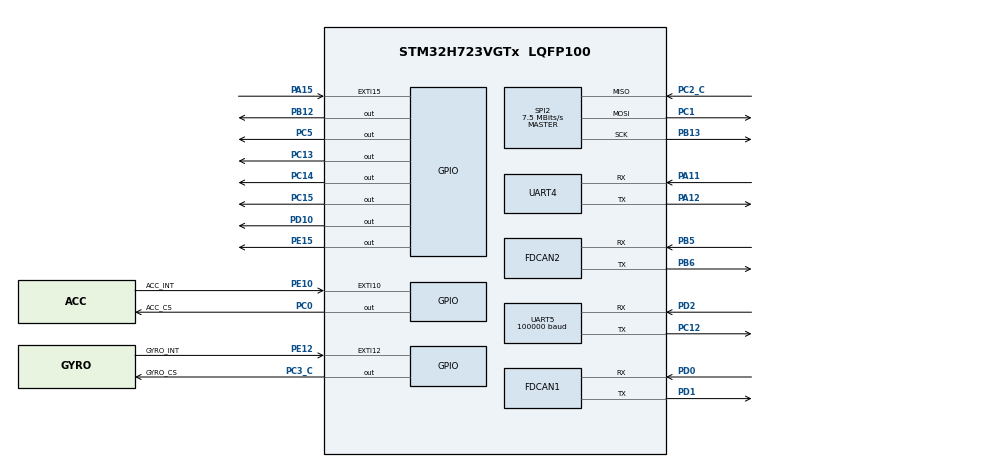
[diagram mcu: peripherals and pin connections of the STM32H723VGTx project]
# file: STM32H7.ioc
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Dma.Request0=UART5_RX
Dma.Request1=UART4_RX
Dma.Request2=UART4_TX
Dma.Request3=SPI2_RX
Dma.Request4=SPI2_TX
Dma.SPI2_RX.3.Direction=DMA_PERIPH_TO_MEMORY
Dma.SPI2_RX.3.EventEnable=DISABLE
Dma.SPI2_RX.3.FIFOMode=DMA_FIFOMODE_DISABLE
Dma.SPI2_RX.3.Instance=DMA1_Stream0
Dma.SPI2_RX.3.MemDataAlignment=DMA_MDATAALIGN_BYTE
Dma.SPI2_RX.3.MemInc=DMA_MINC_ENABLE
Dma.SPI2_RX.3.Mode=DMA_NORMAL
Dma.SPI2_RX.3.PeriphDataAlignment=DMA_PDATAALIGN_BYTE
Dma.SPI2_RX.3.PeriphInc=DMA_PINC_DISABLE
Dma.SPI2_RX.3.Polarity=HAL_DMAMUX_REQ_GEN_RISING
Dma.SPI2_RX.3.Priority=DMA_PRIORITY_VERY_HIGH
Dma.SPI2_RX.3.RequestNumber=1
Dma.SPI2_RX.3.SignalID=NONE
Dma.SPI2_RX.3.SyncEnable=DISABLE
Dma.SPI2_RX.3.SyncPolarity=HAL_DMAMUX_SYNC_NO_EVENT
Dma.SPI2_RX.3.SyncRequestNumber=1
Dma.SPI2_RX.3.SyncSignalID=NONE
Dma.SPI2_TX.4.Direction=DMA_MEMORY_TO_PERIPH
Dma.SPI2_TX.4.EventEnable=DISABLE
Dma.SPI2_TX.4.FIFOMode=DMA_FIFOMODE_DISABLE
Dma.SPI2_TX.4.Instance=DMA1_Stream1
Dma.SPI2_TX.4.MemDataAlignment=DMA_MDATAALIGN_BYTE
Dma.SPI2_TX.4.MemInc=DMA_MINC_ENABLE
Dma.SPI2_TX.4.Mode=DMA_NORMAL
Dma.SPI2_TX.4.PeriphDataAlignment=DMA_PDATAALIGN_BYTE
Dma.SPI2_TX.4.PeriphInc=DMA_PINC_DISABLE
Dma.SPI2_TX.4.Polarity=HAL_DMAMUX_REQ_GEN_RISING
Dma.SPI2_TX.4.Priority=DMA_PRIORITY_HIGH
Dma.SPI2_TX.4.RequestNumber=1
Dma.SPI2_TX.4.SignalID=NONE
Dma.SPI2_TX.4.SyncEnable=DISABLE
Dma.SPI2_TX.4.SyncPolarity=HAL_DMAMUX_SYNC_NO_EVENT
Dma.SPI2_TX.4.SyncRequestNumber=1
Dma.SPI2_TX.4.SyncSignalID=NONE
Dma.UART4_RX.1.Direction=DMA_PERIPH_TO_MEMORY
Dma.UART4_RX.1.EventEnable=DISABLE
Dma.UART4_RX.1.FIFOMode=DMA_FIFOMODE_DISABLE
Dma.UART4_RX.1.Instance=DMA1_Stream3
Dma.UART4_RX.1.MemDataAlignment=DMA_MDATAALIGN_BYTE
Dma.UART4_RX.1.MemInc=DMA_MINC_ENABLE
Dma.UART4_RX.1.Mode=DMA_NORMAL
Dma.UART4_RX.1.PeriphDataAlignment=DMA_PDATAALIGN_BYTE
Dma.UART4_RX.1.PeriphInc=DMA_PINC_DISABLE
Dma.UART4_RX.1.Polarity=HAL_DMAMUX_REQ_GEN_RISING
Dma.UART4_RX.1.Priority=DMA_PRIORITY_HIGH
Dma.UART4_RX.1.RequestNumber=1
Dma.UART4_RX.1.SignalID=NONE
Dma.UART4_RX.1.SyncEnable=DISABLE
Dma.UART4_RX.1.SyncPolarity=HAL_DMAMUX_SYNC_NO_EVENT
Dma.UART4_RX.1.SyncRequestNumber=1
Dma.UART4_RX.1.SyncSignalID=NONE
Dma.UART4_TX.2.Direction=DMA_MEMORY_TO_PERIPH
Dma.UART4_TX.2.EventEnable=DISABLE
Dma.UART4_TX.2.FIFOMode=DMA_FIFOMODE_DISABLE
Dma.UART4_TX.2.Instance=DMA1_Stream4
Dma.UART4_TX.2.MemDataAlignment=DMA_MDATAALIGN_BYTE
Dma.UART4_TX.2.MemInc=DMA_MINC_ENABLE
Dma.UART4_TX.2.Mode=DMA_NORMAL
Dma.UART4_TX.2.PeriphDataAlignment=DMA_PDATAALIGN_BYTE
Dma.UART4_TX.2.PeriphInc=DMA_PINC_DISABLE
Dma.UART4_TX.2.Polarity=HAL_DMAMUX_REQ_GEN_RISING
Dma.UART4_TX.2.Priority=DMA_PRIORITY_HIGH
Dma.UART4_TX.2.RequestNumber=1
Dma.UART4_TX.2.SignalID=NONE
Dma.UART4_TX.2.SyncEnable=DISABLE
Dma.UART4_TX.2.SyncPolarity=HAL_DMAMUX_SYNC_NO_EVENT
Dma.UART4_TX.2.SyncRequestNumber=1
Dma.UART4_TX.2.SyncSignalID=NONE
Dma.UART5_RX.0.Direction=DMA_PERIPH_TO_MEMORY
Dma.UART5_RX.0.EventEnable=DISABLE
Dma.UART5_RX.0.FIFOMode=DMA_FIFOMODE_DISABLE
Dma.UART5_RX.0.Instance=DMA1_Stream2
Dma.UART5_RX.0.MemDataAlignment=DMA_MDATAALIGN_BYTE
Dma.UART5_RX.0.MemInc=DMA_MINC_ENABLE
Dma.UART5_RX.0.Mode=DMA_NORMAL
Dma.UART5_RX.0.PeriphDataAlignment=DMA_PDATAALIGN_BYTE
Dma.UART5_RX.0.PeriphInc=DMA_PINC_DISABLE
Dma.UART5_RX.0.Polarity=HAL_DMAMUX_REQ_GEN_RISING
Dma.UART5_RX.0.Priority=DMA_PRIORITY_MEDIUM
Dma.UART5_RX.0.RequestNumber=1
Dma.UART5_RX.0.SignalID=NONE
Dma.UART5_RX.0.SyncEnable=DISABLE
Dma.UART5_RX.0.SyncPolarity=HAL_DMAMUX_SYNC_NO_EVENT
Dma.UART5_RX.0.SyncRequestNumber=1
Dma.UART5_RX.0.SyncSignalID=NONE
FDCAN1.AutoRetransmission=DISABLE
FDCAN1.CalculateBaudRateNominal=1000000
FDCAN1.CalculateTimeBitNominal=1000
FDCAN1.CalculateTimeQuantumNominal=40.0
FDCAN1.DataPrescaler=4
FDCAN1.DataSyncJumpWidth=1
FDCAN1.DataTimeSeg1=19
FDCAN1.DataTimeSeg2=5
FDCAN1.ExtFiltersNbr=5
FDCAN1.FrameFormat=FDCAN_FRAME_CLASSIC
FDCAN1.NominalPrescaler=4
FDCAN1.NominalTimeSeg1=19
FDCAN1.NominalTimeSeg2=5
FDCAN1.ProtocolException=DISABLE
FDCAN1.RxFifo0ElmtSize=FDCAN_DATA_BYTES_24
FDCAN1.RxFifo0ElmtsNbr=4
FDCAN1.RxFifo1ElmtSize=FDCAN_DATA_BYTES_24
FDCAN1.RxFifo1ElmtsNbr=0
FDCAN1.StdFiltersNbr=5
FDCAN1.TransmitPause=DISABLE
FDCAN1.TxElmtSize=FDCAN_DATA_BYTES_24
FDCAN1.TxFifoQueueElmtsNbr=8
FDCAN2.CalculateBaudRateNominal=1000000
FDCAN2.CalculateTimeBitNominal=1000
FDCAN2.CalculateTimeQuantumNominal=50.0
FDCAN2.DataPrescaler=5
FDCAN2.DataSyncJumpWidth=1
FDCAN2.DataTimeSeg1=14
FDCAN2.DataTimeSeg2=5
FDCAN2.ExtFiltersNbr=5
FDCAN2.FrameFormat=FDCAN_FRAME_CLASSIC
FDCAN2.MessageRAMOffset=854
FDCAN2.NominalPrescaler=5
FDCAN2.NominalTimeSeg1=14
FDCAN2.NominalTimeSeg2=5
FDCAN2.ProtocolException=DISABLE
FDCAN2.RxFifo0ElmtsNbr=0
FDCAN2.RxFifo1ElmtSize=FDCAN_DATA_BYTES_24
FDCAN2.RxFifo1ElmtsNbr=4
FDCAN2.StdFiltersNbr=5
FDCAN2.TxElmtSize=FDCAN_DATA_BYTES_16
FDCAN2.TxFifoQueueElmtsNbr=4
Mcu.Family=STM32H7
Mcu.Name=STM32H723VGTx
Mcu.Package=LQFP100
NVIC.DMA1_Stream0_IRQn=true\:1\:0\:true\:false\:true\:false\:true\:true
NVIC.DMA1_Stream1_IRQn=true\:1\:0\:true\:false\:true\:false\:true\:true
NVIC.DMA1_Stream2_IRQn=true\:0\:0\:true\:false\:true\:false\:true\:true
NVIC.DMA1_Stream3_IRQn=true\:0\:0\:false\:false\:true\:false\:true\:true
NVIC.DMA1_Stream4_IRQn=true\:0\:0\:false\:false\:true\:false\:true\:true
NVIC.FDCAN1_IT0_IRQn=true\:2\:0\:true\:false\:true\:true\:true\:true
NVIC.FDCAN2_IT0_IRQn=true\:1\:0\:true\:false\:true\:true\:true\:true
NVIC.PriorityGroup=NVIC_PRIORITYGROUP_4
NVIC.SPI2_IRQn=true\:0\:0\:false\:false\:true\:false\:true\:true
NVIC.TIM8_TRG_COM_TIM14_IRQn=true\:0\:0\:false\:false\:true\:true\:true\:true
NVIC.UART4_IRQn=true\:1\:0\:true\:false\:true\:true\:true\:true
NVIC.UART5_IRQn=true\:3\:0\:true\:false\:true\:true\:true\:true
PA11.Mode=Asynchronous
PA11.Signal=UART4_RX
PA12.Mode=Asynchronous
PA12.Signal=UART4_TX
PA13(JTMS/SWDIO).Mode=Serial_Wire
PA13(JTMS/SWDIO).Signal=DEBUG_JTMS-SWDIO
PA14(JTCK/SWCLK).Mode=Serial_Wire
PA14(JTCK/SWCLK).Signal=DEBUG_JTCK-SWCLK
PA15(JTDI).Signal=GPXTI15
PB12.Signal=GPIO_Output
PB13.Mode=Full_Duplex_Master
PB13.Signal=SPI2_SCK
PB5.Mode=FDCAN_Activate
PB5.Signal=FDCAN2_RX
PB6.Mode=FDCAN_Activate
PB6.Signal=FDCAN2_TX
PC0.GPIO_Label=ACC_CS
PC0.GPIO_Speed=GPIO_SPEED_FREQ_VERY_HIGH
PC0.PinState=GPIO_PIN_SET
PC0.Signal=GPIO_Output
PC1.Mode=Full_Duplex_Master
PC1.Signal=SPI2_MOSI
PC12.Mode=Asynchronous
PC12.Signal=UART5_TX
PC13.Signal=GPIO_Output
PC14-OSC32_IN.PinState=GPIO_PIN_RESET
PC14-OSC32_IN.Signal=GPIO_Output
PC15-OSC32_OUT.Signal=GPIO_Output
PC2_C.Mode=Full_Duplex_Master
PC2_C.Signal=SPI2_MISO
PC3_C.GPIO_Label=GYRO_CS
PC3_C.GPIO_Speed=GPIO_SPEED_FREQ_VERY_HIGH
PC3_C.PinState=GPIO_PIN_SET
PC3_C.Signal=GPIO_Output
PC5.Signal=GPIO_Output
PD0.Mode=FDCAN_Activate
PD0.Signal=FDCAN1_RX
PD1.Mode=FDCAN_Activate
PD1.Signal=FDCAN1_TX
PD10.Signal=GPIO_Output
PD2.Mode=Asynchronous
PD2.Signal=UART5_RX
PE10.GPIO_Label=ACC_INT
PE10.Signal=GPXTI10
PE12.GPIO_Label=GYRO_INT
PE12.Signal=GPXTI12
PE15.Signal=GPIO_Output
PH0-OSC_IN.Mode=HSE-External-Oscillator
PH0-OSC_IN.Signal=RCC_OSC_IN
PH1-OSC_OUT.Mode=HSE-External-Oscillator
PH1-OSC_OUT.Signal=RCC_OSC_OUT
ProjectManager.HeapSize=0x200
ProjectManager.StackSize=0x400
ProjectManager.TargetToolchain=MDK-ARM V5.32
RCC.ADCFreq_Value=100000000
RCC.APB1Freq_Value=120000000
RCC.APB2Freq_Value=120000000
RCC.APB3Freq_Value=120000000
RCC.APB4Freq_Value=120000000
RCC.CortexFreq_Value=480000000
RCC.D1PPRE=RCC_APB3_DIV2
RCC.D2PPRE1=RCC_APB1_DIV2
RCC.D2PPRE2=RCC_APB2_DIV2
RCC.D3PPRE=RCC_APB4_DIV2
RCC.DIVM1=2
RCC.DIVM2=24
RCC.DIVN1=40
RCC.DIVN2=200
RCC.DIVP1=1
RCC.FDCANCLockSelection=RCC_FDCANCLKSOURCE_PLL2
RCC.HCLKFreq_Value=240000000
RCC.HPRE=RCC_HCLK_DIV2
RCC.HSE_VALUE=24000000
RCC.PLL2FRACN=0
RCC.PLL3FRACN=0
RCC.PLLFRACN=0
RCC.PLLSourceVirtual=RCC_PLLSOURCE_HSE
RCC.RCC_MCO1Source=RCC_MCO1SOURCE_HSE
RCC.SYSCLKFreq_VALUE=480000000
RCC.SYSCLKSource=RCC_SYSCLKSOURCE_PLLCLK
RCC.USBCLockSelection=RCC_USBCLKSOURCE_HSI48
RCC.USBFreq_Value=48000000
SPI2.BaudRatePrescaler=SPI_BAUDRATEPRESCALER_32
SPI2.CLKPhase=SPI_PHASE_2EDGE
SPI2.CLKPolarity=SPI_POLARITY_HIGH
SPI2.CalculateBaudRate=7.5 MBits/s
SPI2.DataSize=SPI_DATASIZE_8BIT
SPI2.Direction=SPI_DIRECTION_2LINES
SPI2.Mode=SPI_MODE_MASTER
SPI2.VirtualType=VM_MASTER
TIM14.Period=1000-1
TIM14.Prescaler=240-1
UART5.BaudRate=100000
UART5.Parity=PARITY_EVEN
UART5.StopBits=UART_STOPBITS_2
UART5.WordLength=WORDLENGTH_9B
VP_TIM14_VS_ClockSourceINT.Mode=Enable_Timer
board=custom

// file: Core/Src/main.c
/* USER CODE BEGIN Header */
/**
  ******************************************************************************
  * @file           : main.c
  * @brief          : Main program body
  ******************************************************************************
  * @attention
  *
  * Copyright (c) 2024 STMicroelectronics.
  * All rights reserved.
  *
  * This software is licensed under terms that can be found in the LICENSE file
  * in the root directory of this software component.
  * If no LICENSE file comes with this software, it is provided AS-IS.
  *
  ******************************************************************************
  */
/* USER CODE END Header */
#include "main.h"
#include "dma.h"
#include "fdcan.h"
#include "spi.h"
#include "tim.h"
#include "usart.h"
#include "gpio.h"

/* USER CODE BEGIN Includes */
#include "hardware_config.h"
/* USER CODE END Includes */

void SystemClock_Config(void);
void PeriphCommonClock_Config(void);

int main(void)
{
  /* USER CODE BEGIN 1 */
//01 08 00 00 02 00 00 00
  /* USER CODE END 1 */

  /* MCU Configuration--------------------------------------------------------*/

  /* Reset of all peripherals, Initializes the Flash interface and the Systick. */
  HAL_Init();

  /* Configure the system clock */
  SystemClock_Config();

/* Configure the peripherals common clocks */
  PeriphCommonClock_Config();

  /* Initialize all configured peripherals */
  MX_GPIO_Init();
  MX_DMA_Init();
  MX_FDCAN1_Init();
  MX_FDCAN2_Init();
  MX_UART5_Init();
  MX_UART4_Init();
  MX_TIM14_Init();
  MX_SPI2_Init();
  /* USER CODE BEGIN 2 */
	HardwareConfig();

  /* USER CODE END 2 */

  /* Infinite loop */
  while (1)
  {

  }
}

void SystemClock_Config(void)
{
  RCC_OscInitTypeDef RCC_OscInitStruct = {0};
  RCC_ClkInitTypeDef RCC_ClkInitStruct = {0};

  /** Supply configuration update enable
  */
  HAL_PWREx_ConfigSupply(PWR_LDO_SUPPLY);

  /** Configure the main internal regulator output voltage
  */
  __HAL_PWR_VOLTAGESCALING_CONFIG(PWR_REGULATOR_VOLTAGE_SCALE0);

  while(!__HAL_PWR_GET_FLAG(PWR_FLAG_VOSRDY)) {}

  /** Initializes the RCC Oscillators according to the specified parameters
  * in the RCC_OscInitTypeDef structure.
  */
  RCC_OscInitStruct.OscillatorType = RCC_OSCILLATORTYPE_HSE;
  RCC_OscInitStruct.HSEState = RCC_HSE_ON;
  RCC_OscInitStruct.PLL.PLLState = RCC_PLL_ON;
  RCC_OscInitStruct.PLL.PLLSource = RCC_PLLSOURCE_HSE;
  RCC_OscInitStruct.PLL.PLLM = 2;
  RCC_OscInitStruct.PLL.PLLN = 40;
  RCC_OscInitStruct.PLL.PLLP = 1;
  RCC_OscInitStruct.PLL.PLLQ = 2;
  RCC_OscInitStruct.PLL.PLLR = 2;
  RCC_OscInitStruct.PLL.PLLRGE = RCC_PLL1VCIRANGE_3;
  RCC_OscInitStruct.PLL.PLLVCOSEL = RCC_PLL1VCOWIDE;
  RCC_OscInitStruct.PLL.PLLFRACN = 0;
  if (HAL_RCC_OscConfig(&RCC_OscInitStruct) != HAL_OK)
  {
    Error_Handler();
  }

  /** Initializes the CPU, AHB and APB buses clocks
  */
  RCC_ClkInitStruct.ClockType = RCC_CLOCKTYPE_HCLK|RCC_CLOCKTYPE_SYSCLK
                              |RCC_CLOCKTYPE_PCLK1|RCC_CLOCKTYPE_PCLK2
                              |RCC_CLOCKTYPE_D3PCLK1|RCC_CLOCKTYPE_D1PCLK1;
  RCC_ClkInitStruct.SYSCLKSource = RCC_SYSCLKSOURCE_PLLCLK;
  RCC_ClkInitStruct.SYSCLKDivider = RCC_SYSCLK_DIV1;
  RCC_ClkInitStruct.AHBCLKDivider = RCC_HCLK_DIV2;
  RCC_ClkInitStruct.APB3CLKDivider = RCC_APB3_DIV2;
  RCC_ClkInitStruct.APB1CLKDivider = RCC_APB1_DIV2;
  RCC_ClkInitStruct.APB2CLKDivider = RCC_APB2_DIV2;
  RCC_ClkInitStruct.APB4CLKDivider = RCC_APB4_DIV2;

  if (HAL_RCC_ClockConfig(&RCC_ClkInitStruct, FLASH_LATENCY_3) != HAL_OK)
  {
    Error_Handler();
  }
}

void PeriphCommonClock_Config(void)
{
  RCC_PeriphCLKInitTypeDef PeriphClkInitStruct = {0};

  /** Initializes the peripherals clock
  */
  PeriphClkInitStruct.PeriphClockSelection = RCC_PERIPHCLK_FDCAN;
  PeriphClkInitStruct.PLL2.PLL2M = 24;
  PeriphClkInitStruct.PLL2.PLL2N = 200;
  PeriphClkInitStruct.PLL2.PLL2P = 2;
  PeriphClkInitStruct.PLL2.PLL2Q = 2;
  PeriphClkInitStruct.PLL2.PLL2R = 2;
  PeriphClkInitStruct.PLL2.PLL2RGE = RCC_PLL2VCIRANGE_0;
  PeriphClkInitStruct.PLL2.PLL2VCOSEL = RCC_PLL2VCOMEDIUM;
  PeriphClkInitStruct.PLL2.PLL2FRACN = 0;
  PeriphClkInitStruct.FdcanClockSelection = RCC_FDCANCLKSOURCE_PLL2;
  if (HAL_RCCEx_PeriphCLKConfig(&PeriphClkInitStruct) != HAL_OK)
  {
    Error_Handler();
  }
}

void Error_Handler(void)
{
  __disable_irq();
  while (1)
  {
  }
}
